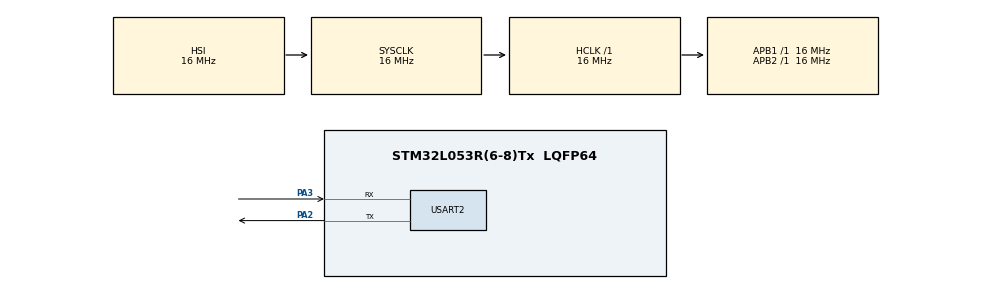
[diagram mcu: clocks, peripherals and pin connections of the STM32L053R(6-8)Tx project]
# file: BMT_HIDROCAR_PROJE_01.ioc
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Mcu.Family=STM32L0
Mcu.Name=STM32L053R(6-8)Tx
Mcu.Package=LQFP64
PA13.Mode=Serial_Wire
PA13.Signal=SYS_SWDIO
PA14.Mode=Serial_Wire
PA14.Signal=SYS_SWCLK
PA2.Mode=Asynchronous
PA2.Signal=USART2_TX
PA3.Mode=Asynchronous
PA3.Signal=USART2_RX
ProjectManager.HeapSize=0x200
ProjectManager.StackSize=0x400
ProjectManager.TargetToolchain=STM32CubeIDE
RCC.AHBFreq_Value=16000000
RCC.APB1Freq_Value=16000000
RCC.APB1TimFreq_Value=16000000
RCC.APB2Freq_Value=16000000
RCC.APB2TimFreq_Value=16000000
RCC.HCLKFreq_Value=16000000
RCC.HSE_VALUE=8000000
RCC.HSI16_VALUE=16000000
RCC.HSI48_VALUE=48000000
RCC.HSI_VALUE=16000000
RCC.LSE_VALUE=32768
RCC.MSI_VALUE=2097000
RCC.SYSCLKFreq_VALUE=16000000
RCC.SYSCLKSource=RCC_SYSCLKSOURCE_HSI
RCC.VCOOutputFreq_Value=48000000
USART2.VirtualMode-Asynchronous=VM_ASYNC
board=custom

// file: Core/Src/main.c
/* USER CODE BEGIN Header */
/**
  ******************************************************************************
  * @file           : main.c
  * @brief          : Main program body
  ******************************************************************************
  * @attention
  *
  * Copyright (c) 2025 STMicroelectronics.
  * All rights reserved.
  *
  * This software is licensed under terms that can be found in the LICENSE file
  * in the root directory of this software component.
  * If no LICENSE file comes with this software, it is provided AS-IS.
  *
  ******************************************************************************
  */
/* USER CODE END Header */
#include "main.h"
#include "usart.h"
#include "gpio.h"

/* USER CODE BEGIN Includes */
#include <stdio.h>
#include <stdlib.h>
#include <string.h>

/* USER CODE END Includes */

/* USER CODE BEGIN PV */
int volt = 0;
int temp = 0;
int extreme_value = 0;
char buffer[64];
uint32_t time_ms = 0; //ölçüm zamanı (ms cinsinden)
/* USER CODE END PV */

void SystemClock_Config(void);
/* USER CODE BEGIN PFP */
void uart_print(char *msg); 		//UART'a mesaj göndermek için kullanılacak fonksiyon prototipi
/* USER CODE END PFP */

/* USER CODE BEGIN 0 */

//UART üzerinden string gönderme fonksiyonu
void uart_print(char *msg){
	HAL_UART_Transmit(&huart2,(uint8_t*)msg, strlen(msg), HAL_MAX_DELAY);
}
/* USER CODE END 0 */

int main(void)
{

  /* MCU Configuration--------------------------------------------------------*/

  /* Reset of all peripherals, Initializes the Flash interface and the Systick. */
  HAL_Init();

  /* Configure the system clock */
  SystemClock_Config();

  /* Initialize all configured peripherals */
  MX_GPIO_Init();
  MX_USART2_UART_Init();
  /* USER CODE BEGIN 2 */

  srand(HAL_GetTick()); 				// rastgele değer üreten fonksiyon
  uart_print("time,temp,volt\r\n");     // CSV başlık satırı
  uint32_t count = 0;				    // değerleri 10 saniye boyunca almamızı sağlayacak sayaç

  /* USER CODE END 2 */

  /* Infinite loop */
  /* USER CODE BEGIN WHILE */
  while (1)
  {
	  if(count < 100) 									// 10 saniye boyunca ölçüm yap
	  {
		  HAL_Delay(100); 								// 100ms bekle
		  time_ms += 100;			   			   	    // toplam süreyi 100ms artır
		  count++; 		               					// sayaçı 1 artır

		  extreme_value = (rand() % 100 < 3);       // %3 ihtimalle sınırdışı değer üret
		  temp = 20 + rand() % 36;					// normal sıcaklık 20-55°C aralığında
		  if(extreme_value)
			  temp = 56 + rand() % 10;					// sınırdışı durumda sıcaklık 56-65°C aralığında

		  volt = 55 + rand() % 18;					// normal voltaj 55-72V aralığında
		  if(extreme_value)
			  volt = 50 + rand() % 5;					// sınırdışı durumda voltaj 50-54V aralığında

		  											//UART ile gönderilecek veriyi tutan buffer
		  sprintf(buffer, "%lu,%d,%d\r\n", time_ms, temp, volt); 		// CSV formatında string oluştur
		  uart_print(buffer);  											// UART üzerinden gönder

		  //sınırdışı değerler için uyarılar

		  if(volt < 60 && temp > 50){
			  uart_print("!!! SYSTEM ERROR !!!\r\n");					// sistem hata durumuna geçti
		  }
		  else if(volt < 60){
			  uart_print("!!! LOW VOLTAGE WARNING !!! \r\n");			// düşük voltaj uyarısı
		  }
		  else if(temp > 50){
			  uart_print("!!! OVER TEMPERATURE !!! \r\n");				// yüksek sıcaklık uyarısı
		  }

	  }
    /* USER CODE END WHILE */

  }
}

void SystemClock_Config(void)
{
  RCC_OscInitTypeDef RCC_OscInitStruct = {0};
  RCC_ClkInitTypeDef RCC_ClkInitStruct = {0};
  RCC_PeriphCLKInitTypeDef PeriphClkInit = {0};

  /** Configure the main internal regulator output voltage
  */
  __HAL_PWR_VOLTAGESCALING_CONFIG(PWR_REGULATOR_VOLTAGE_SCALE1);

  /** Initializes the RCC Oscillators according to the specified parameters
  * in the RCC_OscInitTypeDef structure.
  */
  RCC_OscInitStruct.OscillatorType = RCC_OSCILLATORTYPE_HSI;
  RCC_OscInitStruct.HSIState = RCC_HSI_ON;
  RCC_OscInitStruct.HSICalibrationValue = RCC_HSICALIBRATION_DEFAULT;
  RCC_OscInitStruct.PLL.PLLState = RCC_PLL_NONE;
  if (HAL_RCC_OscConfig(&RCC_OscInitStruct) != HAL_OK)
  {
    Error_Handler();
  }

  /** Initializes the CPU, AHB and APB buses clocks
  */
  RCC_ClkInitStruct.ClockType = RCC_CLOCKTYPE_HCLK|RCC_CLOCKTYPE_SYSCLK
                              |RCC_CLOCKTYPE_PCLK1|RCC_CLOCKTYPE_PCLK2;
  RCC_ClkInitStruct.SYSCLKSource = RCC_SYSCLKSOURCE_HSI;
  RCC_ClkInitStruct.AHBCLKDivider = RCC_SYSCLK_DIV1;
  RCC_ClkInitStruct.APB1CLKDivider = RCC_HCLK_DIV1;
  RCC_ClkInitStruct.APB2CLKDivider = RCC_HCLK_DIV1;

  if (HAL_RCC_ClockConfig(&RCC_ClkInitStruct, FLASH_LATENCY_0) != HAL_OK)
  {
    Error_Handler();
  }
  PeriphClkInit.PeriphClockSelection = RCC_PERIPHCLK_USART2;
  PeriphClkInit.Usart2ClockSelection = RCC_USART2CLKSOURCE_PCLK1;
  if (HAL_RCCEx_PeriphCLKConfig(&PeriphClkInit) != HAL_OK)
  {
    Error_Handler();
  }
}

void Error_Handler(void)
{
  __disable_irq();
  while (1)
  {
  }
}
